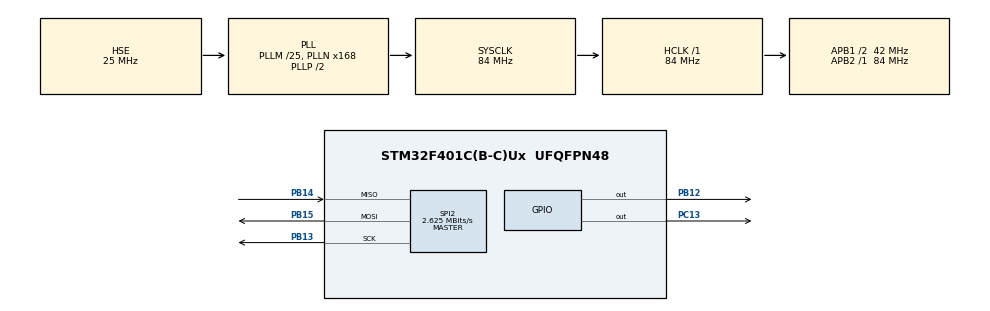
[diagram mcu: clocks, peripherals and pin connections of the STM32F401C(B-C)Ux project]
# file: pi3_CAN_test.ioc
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FREERTOS.Tasks01=defaultTask,0,128,StartDefaultTask,Default,NULL,Dynamic,NULL,NULL;Task_MCP2515,0,512,Task_MCP2515_start,Default,NULL,Dynamic,NULL,NULL
FREERTOS.configENABLE_FPU=1
Mcu.Family=STM32F4
Mcu.Name=STM32F401C(B-C)Ux
Mcu.Package=UFQFPN48
NVIC.PriorityGroup=NVIC_PRIORITYGROUP_4
NVIC.TIM2_IRQn=true\:15\:0\:false\:false\:true\:false\:false\:true\:true
NVIC.TimeBase=TIM2_IRQn
NVIC.TimeBaseIP=TIM2
PA13.Mode=Serial_Wire
PA13.Signal=SYS_JTMS-SWDIO
PA14.Mode=Serial_Wire
PA14.Signal=SYS_JTCK-SWCLK
PB12.Signal=GPIO_Output
PB13.Mode=Full_Duplex_Master
PB13.Signal=SPI2_SCK
PB14.Mode=Full_Duplex_Master
PB14.Signal=SPI2_MISO
PB15.Mode=Full_Duplex_Master
PB15.Signal=SPI2_MOSI
PC13-ANTI_TAMP.Signal=GPIO_Output
PC14-OSC32_IN.Mode=LSE-External-Oscillator
PC14-OSC32_IN.Signal=RCC_OSC32_IN
PC15-OSC32_OUT.Mode=LSE-External-Oscillator
PC15-OSC32_OUT.Signal=RCC_OSC32_OUT
PH0\ -\ OSC_IN.Mode=HSE-External-Oscillator
PH0\ -\ OSC_IN.Signal=RCC_OSC_IN
PH1\ -\ OSC_OUT.Mode=HSE-External-Oscillator
PH1\ -\ OSC_OUT.Signal=RCC_OSC_OUT
ProjectManager.HeapSize=0x200
ProjectManager.StackSize=0x400
ProjectManager.TargetToolchain=STM32CubeIDE
RCC.48MHZClocksFreq_Value=42000000
RCC.AHBFreq_Value=84000000
RCC.APB1CLKDivider=RCC_HCLK_DIV2
RCC.APB1Freq_Value=42000000
RCC.APB1TimFreq_Value=84000000
RCC.APB2Freq_Value=84000000
RCC.APB2TimFreq_Value=84000000
RCC.CortexFreq_Value=84000000
RCC.HCLKFreq_Value=84000000
RCC.HSE_VALUE=25000000
RCC.HSI_VALUE=16000000
RCC.PLLM=25
RCC.PLLN=168
RCC.PLLSourceVirtual=RCC_PLLSOURCE_HSE
RCC.SYSCLKFreq_VALUE=84000000
RCC.SYSCLKSource=RCC_SYSCLKSOURCE_PLLCLK
RCC.VCOOutputFreq_Value=168000000
SPI2.BaudRatePrescaler=SPI_BAUDRATEPRESCALER_16
SPI2.CLKPhase=SPI_PHASE_2EDGE
SPI2.CLKPolarity=SPI_POLARITY_HIGH
SPI2.CalculateBaudRate=2.625 MBits/s
SPI2.Direction=SPI_DIRECTION_2LINES
SPI2.Mode=SPI_MODE_MASTER
SPI2.VirtualType=VM_MASTER
VP_FREERTOS_VS_CMSIS_V1.Mode=CMSIS_V1
VP_SYS_VS_tim2.Mode=TIM2
board=custom

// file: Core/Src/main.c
/* USER CODE BEGIN Header */
/**
  ******************************************************************************
  * @file           : main.c
  * @brief          : Main program body
  ******************************************************************************
  * @attention
  *
  * Copyright (c) 2026 STMicroelectronics.
  * All rights reserved.
  *
  * This software is licensed under terms that can be found in the LICENSE file
  * in the root directory of this software component.
  * If no LICENSE file comes with this software, it is provided AS-IS.
  *
  ******************************************************************************
  */
/* USER CODE END Header */
#include "main.h"
#include "cmsis_os.h"

/* USER CODE BEGIN Includes */

#include "MCP2515_driver.h"

/* USER CODE END Includes */

SPI_HandleTypeDef hspi2;

osThreadId defaultTaskHandle;
osThreadId Task_MCP2515Handle;

void SystemClock_Config(void);
static void MX_GPIO_Init(void);
static void MX_SPI2_Init(void);
void StartDefaultTask(void const * argument);
void Task_MCP2515_start(void const * argument);

int main(void)
{

  /* MCU Configuration--------------------------------------------------------*/

  /* Reset of all peripherals, Initializes the Flash interface and the Systick. */
  HAL_Init();

  /* Configure the system clock */
  SystemClock_Config();

  /* Initialize all configured peripherals */
  MX_GPIO_Init();
  MX_SPI2_Init();

  /* Create the thread(s) */
  /* definition and creation of defaultTask */
  osThreadDef(defaultTask, StartDefaultTask, osPriorityNormal, 0, 128);
  defaultTaskHandle = osThreadCreate(osThread(defaultTask), NULL);

  /* definition and creation of Task_MCP2515 */
  osThreadDef(Task_MCP2515, Task_MCP2515_start, osPriorityNormal, 0, 512);
  Task_MCP2515Handle = osThreadCreate(osThread(Task_MCP2515), NULL);

  /* Start scheduler */
  osKernelStart();

  /* We should never get here as control is now taken by the scheduler */

  /* Infinite loop */
  while (1)
  {

  }
}

void SystemClock_Config(void)
{
  RCC_OscInitTypeDef RCC_OscInitStruct = {0};
  RCC_ClkInitTypeDef RCC_ClkInitStruct = {0};

  /** Configure the main internal regulator output voltage
  */
  __HAL_RCC_PWR_CLK_ENABLE();
  __HAL_PWR_VOLTAGESCALING_CONFIG(PWR_REGULATOR_VOLTAGE_SCALE2);

  /** Initializes the RCC Oscillators according to the specified parameters
  * in the RCC_OscInitTypeDef structure.
  */
  RCC_OscInitStruct.OscillatorType = RCC_OSCILLATORTYPE_HSE;
  RCC_OscInitStruct.HSEState = RCC_HSE_ON;
  RCC_OscInitStruct.PLL.PLLState = RCC_PLL_ON;
  RCC_OscInitStruct.PLL.PLLSource = RCC_PLLSOURCE_HSE;
  RCC_OscInitStruct.PLL.PLLM = 25;
  RCC_OscInitStruct.PLL.PLLN = 168;
  RCC_OscInitStruct.PLL.PLLP = RCC_PLLP_DIV2;
  RCC_OscInitStruct.PLL.PLLQ = 4;
  if (HAL_RCC_OscConfig(&RCC_OscInitStruct) != HAL_OK)
  {
    Error_Handler();
  }

  /** Initializes the CPU, AHB and APB buses clocks
  */
  RCC_ClkInitStruct.ClockType = RCC_CLOCKTYPE_HCLK|RCC_CLOCKTYPE_SYSCLK
                              |RCC_CLOCKTYPE_PCLK1|RCC_CLOCKTYPE_PCLK2;
  RCC_ClkInitStruct.SYSCLKSource = RCC_SYSCLKSOURCE_PLLCLK;
  RCC_ClkInitStruct.AHBCLKDivider = RCC_SYSCLK_DIV1;
  RCC_ClkInitStruct.APB1CLKDivider = RCC_HCLK_DIV2;
  RCC_ClkInitStruct.APB2CLKDivider = RCC_HCLK_DIV1;

  if (HAL_RCC_ClockConfig(&RCC_ClkInitStruct, FLASH_LATENCY_2) != HAL_OK)
  {
    Error_Handler();
  }
}

static void MX_SPI2_Init(void)
{

  /* SPI2 parameter configuration*/
  hspi2.Instance = SPI2;
  hspi2.Init.Mode = SPI_MODE_MASTER;
  hspi2.Init.Direction = SPI_DIRECTION_2LINES;
  hspi2.Init.DataSize = SPI_DATASIZE_8BIT;
  hspi2.Init.CLKPolarity = SPI_POLARITY_HIGH;
  hspi2.Init.CLKPhase = SPI_PHASE_2EDGE;
  hspi2.Init.NSS = SPI_NSS_SOFT;
  hspi2.Init.BaudRatePrescaler = SPI_BAUDRATEPRESCALER_16;
  hspi2.Init.FirstBit = SPI_FIRSTBIT_MSB;
  hspi2.Init.TIMode = SPI_TIMODE_DISABLE;
  hspi2.Init.CRCCalculation = SPI_CRCCALCULATION_DISABLE;
  hspi2.Init.CRCPolynomial = 10;
  if (HAL_SPI_Init(&hspi2) != HAL_OK)
  {
    Error_Handler();
  }

}

static void MX_GPIO_Init(void)
{
  GPIO_InitTypeDef GPIO_InitStruct = {0};

  /* GPIO Ports Clock Enable */
  __HAL_RCC_GPIOC_CLK_ENABLE();
  __HAL_RCC_GPIOH_CLK_ENABLE();
  __HAL_RCC_GPIOB_CLK_ENABLE();
  __HAL_RCC_GPIOA_CLK_ENABLE();

  /*Configure GPIO pin Output Level */
  HAL_GPIO_WritePin(GPIOC, GPIO_PIN_13, GPIO_PIN_RESET);

  /*Configure GPIO pin Output Level */
  HAL_GPIO_WritePin(GPIOB, GPIO_PIN_12, GPIO_PIN_RESET);

  /*Configure GPIO pin : PC13 */
  GPIO_InitStruct.Pin = GPIO_PIN_13;
  GPIO_InitStruct.Mode = GPIO_MODE_OUTPUT_PP;
  GPIO_InitStruct.Pull = GPIO_NOPULL;
  GPIO_InitStruct.Speed = GPIO_SPEED_FREQ_LOW;
  HAL_GPIO_Init(GPIOC, &GPIO_InitStruct);

  /*Configure GPIO pin : PB12 */
  GPIO_InitStruct.Pin = GPIO_PIN_12;
  GPIO_InitStruct.Mode = GPIO_MODE_OUTPUT_PP;
  GPIO_InitStruct.Pull = GPIO_NOPULL;
  GPIO_InitStruct.Speed = GPIO_SPEED_FREQ_LOW;
  HAL_GPIO_Init(GPIOB, &GPIO_InitStruct);

}

void StartDefaultTask(void const * argument)
{
  /* USER CODE BEGIN 5 */
  /* Infinite loop */
  for(;;)
  {
	HAL_GPIO_TogglePin(GPIOC, GPIO_PIN_13);
    osDelay(1000);
  }
  /* USER CODE END 5 */
}

void Task_MCP2515_start(void const * argument)
{
  /* USER CODE BEGIN Task_MCP2515_start */
	MCP2515_t CAN_controller = {0};
	CAN_controller.hspi = &hspi2;
	CAN_controller.csPort = GPIOB;
	CAN_controller.csPin = GPIO_PIN_12;

	MCP2515_Config(&CAN_controller);

  /* Infinite loop */
  for(;;)
  {
	uint8_t data_L[] = {1, 2, 3, 4};
	MCP2515_TX(&CAN_controller, 0x10, 4, data_L, 0);
    osDelay(1000);
  }
  /* USER CODE END Task_MCP2515_start */
}

void HAL_TIM_PeriodElapsedCallback(TIM_HandleTypeDef *htim)
{
  if (htim->Instance == TIM2)
  {
    HAL_IncTick();
  }
}

void Error_Handler(void)
{
  __disable_irq();
  while (1)
  {
  }
}
